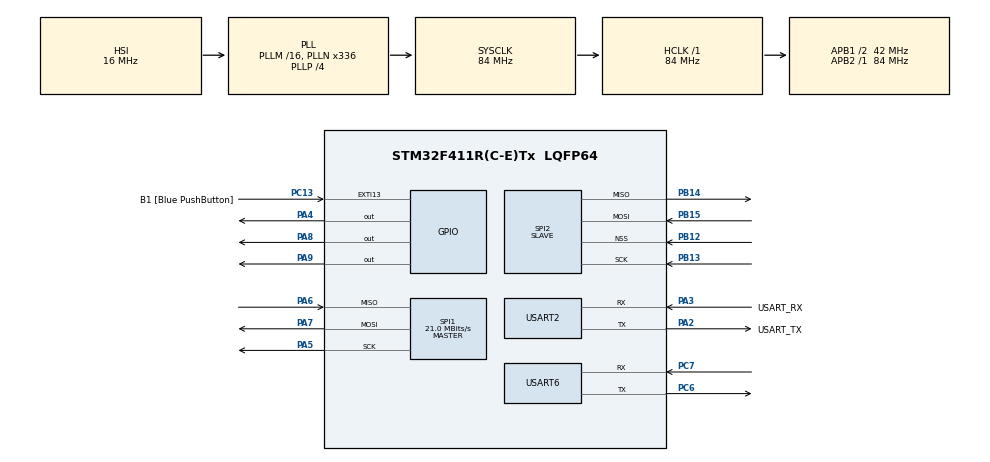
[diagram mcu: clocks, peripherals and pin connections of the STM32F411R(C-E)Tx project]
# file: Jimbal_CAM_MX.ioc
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Dma.Request0=SPI2_RX
Dma.SPI2_RX.0.Direction=DMA_PERIPH_TO_MEMORY
Dma.SPI2_RX.0.FIFOMode=DMA_FIFOMODE_DISABLE
Dma.SPI2_RX.0.Instance=DMA1_Stream3
Dma.SPI2_RX.0.MemDataAlignment=DMA_MDATAALIGN_BYTE
Dma.SPI2_RX.0.MemInc=DMA_MINC_ENABLE
Dma.SPI2_RX.0.Mode=DMA_NORMAL
Dma.SPI2_RX.0.PeriphDataAlignment=DMA_PDATAALIGN_BYTE
Dma.SPI2_RX.0.PeriphInc=DMA_PINC_DISABLE
Dma.SPI2_RX.0.Priority=DMA_PRIORITY_LOW
FREERTOS.Tasks01=defaultTask,24,128,StartDefaultTask,As weak,NULL,Dynamic,NULL,NULL;stackMonitorTas,8,256,StartTask02,As weak,NULL,Dynamic,NULL,NULL
FREERTOS.configCHECK_FOR_STACK_OVERFLOW=2
FREERTOS.configTOTAL_HEAP_SIZE=8192
FREERTOS.configUSE_NEWLIB_REENTRANT=1
Mcu.Family=STM32F4
Mcu.Name=STM32F411R(C-E)Tx
Mcu.Package=LQFP64
NVIC.DMA1_Stream3_IRQn=true\:5\:0\:false\:false\:true\:true\:false\:true\:true
NVIC.PriorityGroup=NVIC_PRIORITYGROUP_4
NVIC.SPI2_IRQn=true\:5\:0\:false\:false\:true\:true\:true\:true\:true
NVIC.TIM1_UP_TIM10_IRQn=true\:0\:0\:true\:false\:true\:false\:false\:true\:true
NVIC.TimeBase=TIM1_UP_TIM10_IRQn
NVIC.TimeBaseIP=TIM10
NVIC.USART2_IRQn=true\:5\:0\:false\:false\:true\:true\:true\:true\:true
NVIC.USART6_IRQn=true\:5\:0\:false\:false\:true\:true\:true\:true\:true
PA13.GPIO_Label=TMS
PA13.Mode=Serial_Wire
PA13.Signal=SYS_JTMS-SWDIO
PA14.GPIO_Label=TCK
PA14.Mode=Serial_Wire
PA14.Signal=SYS_JTCK-SWCLK
PA2.GPIO_Label=USART_TX
PA2.Mode=Asynchronous
PA2.Signal=USART2_TX
PA3.GPIO_Label=USART_RX
PA3.Mode=Asynchronous
PA3.Signal=USART2_RX
PA4.Signal=GPIO_Output
PA5.Mode=Full_Duplex_Master
PA5.Signal=SPI1_SCK
PA6.Mode=Full_Duplex_Master
PA6.Signal=SPI1_MISO
PA7.Mode=Full_Duplex_Master
PA7.Signal=SPI1_MOSI
PA8.Signal=GPIO_Output
PA9.Signal=GPIO_Output
PB12.Mode=NSS_Signal_Hard_Input
PB12.Signal=SPI2_NSS
PB13.Mode=Full_Duplex_Slave
PB13.Signal=SPI2_SCK
PB14.Mode=Full_Duplex_Slave
PB14.Signal=SPI2_MISO
PB15.Mode=Full_Duplex_Slave
PB15.Signal=SPI2_MOSI
PB3.GPIO_Label=SWO
PB3.Signal=SYS_JTDO-SWO
PC13-ANTI_TAMP.GPIO_Label=B1 [Blue PushButton]
PC13-ANTI_TAMP.GPIO_ModeDefaultEXTI=GPIO_MODE_IT_FALLING
PC13-ANTI_TAMP.Signal=GPXTI13
PC14-OSC32_IN.Mode=LSE-External-Oscillator
PC14-OSC32_IN.Signal=RCC_OSC32_IN
PC15-OSC32_OUT.Mode=LSE-External-Oscillator
PC15-OSC32_OUT.Signal=RCC_OSC32_OUT
PC6.Mode=Asynchronous
PC6.Signal=USART6_TX
PC7.Mode=Asynchronous
PC7.Signal=USART6_RX
PH0\ -\ OSC_IN.Mode=HSE-External-Clock-Source
PH0\ -\ OSC_IN.Signal=RCC_OSC_IN
PH1\ -\ OSC_OUT.Mode=HSE-External-Clock-Source
PH1\ -\ OSC_OUT.Signal=RCC_OSC_OUT
ProjectManager.HeapSize=0x200
ProjectManager.StackSize=0x400
ProjectManager.TargetToolchain=CMake
RCC.48MHZClocksFreq_Value=84000000
RCC.AHBFreq_Value=84000000
RCC.APB1CLKDivider=RCC_HCLK_DIV2
RCC.APB1Freq_Value=42000000
RCC.APB1TimFreq_Value=84000000
RCC.APB2Freq_Value=84000000
RCC.APB2TimFreq_Value=84000000
RCC.CortexFreq_Value=84000000
RCC.FLatency-AdvancedSettings=FLASH_LATENCY_2
RCC.HCLKFreq_Value=84000000
RCC.HSE_VALUE=8000000
RCC.HSI_VALUE=16000000
RCC.PLLN=336
RCC.PLLP=RCC_PLLP_DIV4
RCC.SYSCLKFreq_VALUE=84000000
RCC.SYSCLKSource=RCC_SYSCLKSOURCE_PLLCLK
RCC.VCOOutputFreq_Value=336000000
SPI1.BaudRatePrescaler=SPI_BAUDRATEPRESCALER_4
SPI1.CalculateBaudRate=21.0 MBits/s
SPI1.Direction=SPI_DIRECTION_2LINES
SPI1.Mode=SPI_MODE_MASTER
SPI1.VirtualType=VM_MASTER
SPI2.Direction=SPI_DIRECTION_2LINES
SPI2.Mode=SPI_MODE_SLAVE
SPI2.VirtualNSS=VM_NSSHARD
SPI2.VirtualType=VM_SLAVE
USART2.VirtualMode=VM_ASYNC
USART6.VirtualMode=VM_ASYNC
VP_FREERTOS_VS_CMSIS_V2.Mode=CMSIS_V2
VP_SYS_VS_tim10.Mode=TIM10
board=NUCLEO-F411RE

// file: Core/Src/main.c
/* USER CODE BEGIN Header */
/**
  ******************************************************************************
  * @file           : main.c
  * @brief          : Main program body
  ******************************************************************************
  * @attention
  *
  * Copyright (c) 2026 STMicroelectronics.
  * All rights reserved.
  *
  * This software is licensed under terms that can be found in the LICENSE file
  * in the root directory of this software component.
  * If no LICENSE file comes with this software, it is provided AS-IS.
  *
  ******************************************************************************
  */
/* USER CODE END Header */
#include "main.h"
#include "cmsis_os.h"
#include "dma.h"
#include "spi.h"
#include "usart.h"
#include "gpio.h"

/* USER CODE BEGIN Includes */
#include "ap.h"

/* USER CODE END Includes */

void SystemClock_Config(void);
void MX_FREERTOS_Init(void);

int main(void)
{

  /* MCU Configuration--------------------------------------------------------*/

  /* Reset of all peripherals, Initializes the Flash interface and the Systick. */
  HAL_Init();

  /* Configure the system clock */
  SystemClock_Config();

  /* Initialize all configured peripherals */
  MX_GPIO_Init();
  MX_DMA_Init();
  MX_USART2_UART_Init();
  MX_SPI1_Init();
  MX_USART6_UART_Init();
  MX_SPI2_Init();
  /* USER CODE BEGIN 2 */
  //apInit();
  /* USER CODE END 2 */

  /* Init scheduler */
  osKernelInitialize();  /* Call init function for freertos objects (in cmsis_os2.c) */
  MX_FREERTOS_Init();

  /* Start scheduler */
  osKernelStart();

  /* We should never get here as control is now taken by the scheduler */

  /* Infinite loop */
  while (1)
  {

  }
}

void SystemClock_Config(void)
{
  RCC_OscInitTypeDef RCC_OscInitStruct = {0};
  RCC_ClkInitTypeDef RCC_ClkInitStruct = {0};

  /** Configure the main internal regulator output voltage
  */
  __HAL_RCC_PWR_CLK_ENABLE();
  __HAL_PWR_VOLTAGESCALING_CONFIG(PWR_REGULATOR_VOLTAGE_SCALE1);

  /** Initializes the RCC Oscillators according to the specified parameters
  * in the RCC_OscInitTypeDef structure.
  */
  RCC_OscInitStruct.OscillatorType = RCC_OSCILLATORTYPE_HSI;
  RCC_OscInitStruct.HSIState = RCC_HSI_ON;
  RCC_OscInitStruct.HSICalibrationValue = RCC_HSICALIBRATION_DEFAULT;
  RCC_OscInitStruct.PLL.PLLState = RCC_PLL_ON;
  RCC_OscInitStruct.PLL.PLLSource = RCC_PLLSOURCE_HSI;
  RCC_OscInitStruct.PLL.PLLM = 16;
  RCC_OscInitStruct.PLL.PLLN = 336;
  RCC_OscInitStruct.PLL.PLLP = RCC_PLLP_DIV4;
  RCC_OscInitStruct.PLL.PLLQ = 4;
  if (HAL_RCC_OscConfig(&RCC_OscInitStruct) != HAL_OK)
  {
    Error_Handler();
  }

  /** Initializes the CPU, AHB and APB buses clocks
  */
  RCC_ClkInitStruct.ClockType = RCC_CLOCKTYPE_HCLK|RCC_CLOCKTYPE_SYSCLK
                              |RCC_CLOCKTYPE_PCLK1|RCC_CLOCKTYPE_PCLK2;
  RCC_ClkInitStruct.SYSCLKSource = RCC_SYSCLKSOURCE_PLLCLK;
  RCC_ClkInitStruct.AHBCLKDivider = RCC_SYSCLK_DIV1;
  RCC_ClkInitStruct.APB1CLKDivider = RCC_HCLK_DIV2;
  RCC_ClkInitStruct.APB2CLKDivider = RCC_HCLK_DIV1;

  if (HAL_RCC_ClockConfig(&RCC_ClkInitStruct, FLASH_LATENCY_2) != HAL_OK)
  {
    Error_Handler();
  }
}

/* USER CODE BEGIN 4 */
#include <stdio.h>

// printf가 호출되면 내부적으로 이 함수가 실행되어 UART2로 데이터를 전송합니다.
int _write(int file, char *ptr, int len) {
    extern UART_HandleTypeDef huart2; // main.c 위에 정의된 huart2를 가져옴
    HAL_UART_Transmit(&huart2, (uint8_t*)ptr, len, HAL_MAX_DELAY);
    return len;
}

/* USER CODE END 4 */

void HAL_TIM_PeriodElapsedCallback(TIM_HandleTypeDef *htim)
{
  if (htim->Instance == TIM10)
  {
    HAL_IncTick();
  }
}

void Error_Handler(void)
{
  __disable_irq();
  while (1)
  {
  }
}

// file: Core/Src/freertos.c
/* USER CODE BEGIN Header */
/**
  ******************************************************************************
  * File Name          : freertos.c
  * Description        : Code for freertos applications
  ******************************************************************************
  * @attention
  *
  * Copyright (c) 2026 STMicroelectronics.
  * All rights reserved.
  *
  * This software is licensed under terms that can be found in the LICENSE file
  * in the root directory of this software component.
  * If no LICENSE file comes with this software, it is provided AS-IS.
  *
  ******************************************************************************
  */
/* USER CODE END Header */

#include "FreeRTOS.h"
#include "task.h"
#include "main.h"
#include "cmsis_os.h"

/* USER CODE BEGIN Includes */
#include "ap.h"

/* USER CODE END Includes */

/* Definitions for defaultTask */
osThreadId_t defaultTaskHandle;
const osThreadAttr_t defaultTask_attributes = {
  .name = "defaultTask",
  .stack_size = 128 * 4,
  .priority = (osPriority_t) osPriorityNormal,
};

void StartDefaultTask(void *argument);

void MX_FREERTOS_Init(void); /* (MISRA C 2004 rule 8.1) */

void MX_FREERTOS_Init(void) {

  /* Create the thread(s) */
  /* creation of defaultTask */
  defaultTaskHandle = osThreadNew(StartDefaultTask, NULL, &defaultTask_attributes);

}

void StartDefaultTask(void *argument)
{
  /* USER CODE BEGIN StartDefaultTask */
  apInit();
  for(;;) {
    apMain();
  }
  /* Infinite loop */
  // for(;;)
  // {
  //   osDelay(1);
  // }
  /* USER CODE END StartDefaultTask */
}
